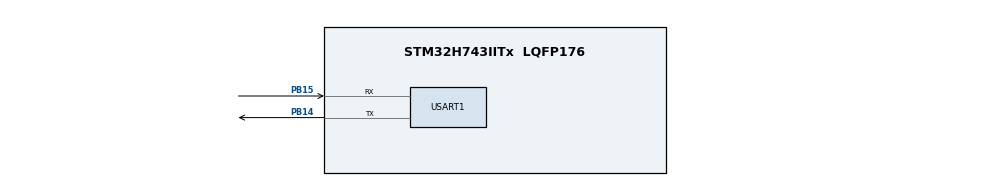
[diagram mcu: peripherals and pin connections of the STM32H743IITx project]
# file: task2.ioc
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CORTEX_M7.CPU_DCache=Enabled
CORTEX_M7.CPU_ICache=Enabled
FREERTOS.Tasks01=defaultTask,24,128,StartDefaultTask,Default,NULL,Dynamic,NULL,NULL
Mcu.Family=STM32H7
Mcu.Name=STM32H743IITx
Mcu.Package=LQFP176
NVIC.PriorityGroup=NVIC_PRIORITYGROUP_4
NVIC.USART1_IRQn=true\:5\:0\:false\:false\:true\:true\:true\:true
PB14.Mode=Asynchronous
PB14.Signal=USART1_TX
PB15.Mode=Asynchronous
PB15.Signal=USART1_RX
PH0-OSC_IN\ (PH0).Mode=HSE-External-Oscillator
PH0-OSC_IN\ (PH0).Signal=RCC_OSC_IN
PH1-OSC_OUT\ (PH1).Mode=HSE-External-Oscillator
PH1-OSC_OUT\ (PH1).Signal=RCC_OSC_OUT
ProjectManager.HeapSize=0x200
ProjectManager.StackSize=0x400
ProjectManager.TargetToolchain=EWARM V8.32
RCC.ADCFreq_Value=50390625
RCC.APB1Freq_Value=100000000
RCC.APB2Freq_Value=100000000
RCC.APB3Freq_Value=100000000
RCC.APB4Freq_Value=100000000
RCC.CortexFreq_Value=400000000
RCC.D1PPRE=RCC_APB3_DIV2
RCC.D2PPRE1=RCC_APB1_DIV2
RCC.D2PPRE2=RCC_APB2_DIV2
RCC.D3PPRE=RCC_APB4_DIV2
RCC.DIVM1=2
RCC.DIVN1=64
RCC.HCLKFreq_Value=200000000
RCC.HPRE=RCC_HCLK_DIV2
RCC.PLLFRACN=0
RCC.PLLSourceVirtual=RCC_PLLSOURCE_HSE
RCC.SYSCLKFreq_VALUE=400000000
RCC.SYSCLKSource=RCC_SYSCLKSOURCE_PLLCLK
RCC.USBFreq_Value=400000000
USART1.VirtualMode-Asynchronous=VM_ASYNC
VP_FREERTOS_VS_CMSIS_V2.Mode=CMSIS_V2
board=custom

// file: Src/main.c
/* USER CODE BEGIN Header */
/**
  ******************************************************************************
  * @file           : main.c
  * @brief          : Main program body
  ******************************************************************************
  * @attention
  *
  * <h2><center>&copy; Copyright (c) 2019 STMicroelectronics.
  * All rights reserved.</center></h2>
  *
  * This software component is licensed by ST under Ultimate Liberty license
  * SLA0044, the "License"; You may not use this file except in compliance with
  * the License. You may obtain a copy of the License at:
  *                             www.st.com/SLA0044
  *
  ******************************************************************************
  */
/* USER CODE END Header */

#include "main.h"
#include "cmsis_os.h"
#include "usart.h"

void SystemClock_Config(void);
void MX_FREERTOS_Init(void);

int main(void)
{

  /* Enable I-Cache---------------------------------------------------------*/
  SCB_EnableICache();

  /* Enable D-Cache---------------------------------------------------------*/
  SCB_EnableDCache();

  /* MCU Configuration--------------------------------------------------------*/

  /* Reset of all peripherals, Initializes the Flash interface and the Systick. */
  HAL_Init();

  /* Configure the system clock */
  SystemClock_Config();

  /* Initialize all configured peripherals */
  MX_USART1_UART_Init();
  /* USER CODE BEGIN 2 */
  BSP_LED_Init();

 // SEGGER_SYSVIEW_Conf();
  SEGGER_RTT_Init();
  /* USER CODE END 2 */

  /* Call init function for freertos objects (in freertos.c) */
  MX_FREERTOS_Init();

  /* Start scheduler */
  osKernelStart();

  /* We should never get here as control is now taken by the scheduler */

  /* Infinite loop */
  while (1)
  {

  }
}

void SystemClock_Config(void)
{
  RCC_OscInitTypeDef RCC_OscInitStruct = {0};
  RCC_ClkInitTypeDef RCC_ClkInitStruct = {0};
  RCC_PeriphCLKInitTypeDef PeriphClkInitStruct = {0};

  /** Supply configuration update enable
  */
  HAL_PWREx_ConfigSupply(PWR_LDO_SUPPLY);
  /** Configure the main internal regulator output voltage
  */
  __HAL_PWR_VOLTAGESCALING_CONFIG(PWR_REGULATOR_VOLTAGE_SCALE1);

  while(!__HAL_PWR_GET_FLAG(PWR_FLAG_VOSRDY)) {}
  /** Initializes the CPU, AHB and APB busses clocks
  */
  RCC_OscInitStruct.OscillatorType = RCC_OSCILLATORTYPE_HSE;
  RCC_OscInitStruct.HSEState = RCC_HSE_ON;
  RCC_OscInitStruct.PLL.PLLState = RCC_PLL_ON;
  RCC_OscInitStruct.PLL.PLLSource = RCC_PLLSOURCE_HSE;
  RCC_OscInitStruct.PLL.PLLM = 2;
  RCC_OscInitStruct.PLL.PLLN = 64;
  RCC_OscInitStruct.PLL.PLLP = 2;
  RCC_OscInitStruct.PLL.PLLQ = 2;
  RCC_OscInitStruct.PLL.PLLR = 2;
  RCC_OscInitStruct.PLL.PLLRGE = RCC_PLL1VCIRANGE_3;
  RCC_OscInitStruct.PLL.PLLVCOSEL = RCC_PLL1VCOWIDE;
  RCC_OscInitStruct.PLL.PLLFRACN = 0;
  if (HAL_RCC_OscConfig(&RCC_OscInitStruct) != HAL_OK)
  {
    Error_Handler();
  }
  /** Initializes the CPU, AHB and APB busses clocks
  */
  RCC_ClkInitStruct.ClockType = RCC_CLOCKTYPE_HCLK|RCC_CLOCKTYPE_SYSCLK
                              |RCC_CLOCKTYPE_PCLK1|RCC_CLOCKTYPE_PCLK2
                              |RCC_CLOCKTYPE_D3PCLK1|RCC_CLOCKTYPE_D1PCLK1;
  RCC_ClkInitStruct.SYSCLKSource = RCC_SYSCLKSOURCE_PLLCLK;
  RCC_ClkInitStruct.SYSCLKDivider = RCC_SYSCLK_DIV1;
  RCC_ClkInitStruct.AHBCLKDivider = RCC_HCLK_DIV2;
  RCC_ClkInitStruct.APB3CLKDivider = RCC_APB3_DIV2;
  RCC_ClkInitStruct.APB1CLKDivider = RCC_APB1_DIV2;
  RCC_ClkInitStruct.APB2CLKDivider = RCC_APB2_DIV2;
  RCC_ClkInitStruct.APB4CLKDivider = RCC_APB4_DIV2;

  if (HAL_RCC_ClockConfig(&RCC_ClkInitStruct, FLASH_LATENCY_2) != HAL_OK)
  {
    Error_Handler();
  }
  PeriphClkInitStruct.PeriphClockSelection = RCC_PERIPHCLK_USART1;
  PeriphClkInitStruct.Usart16ClockSelection = RCC_USART16CLKSOURCE_D2PCLK2;
  if (HAL_RCCEx_PeriphCLKConfig(&PeriphClkInitStruct) != HAL_OK)
  {
    Error_Handler();
  }
}

void Error_Handler(void)
{
}

/************************ (C) COPYRIGHT STMicroelectronics *****END OF FILE****/

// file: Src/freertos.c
/* USER CODE BEGIN Header */
/**
  ******************************************************************************
  * File Name          : freertos.c
  * Description        : Code for freertos applications
  ******************************************************************************
  * @attention
  *
  * <h2><center>&copy; Copyright (c) 2019 STMicroelectronics.
  * All rights reserved.</center></h2>
  *
  * This software component is licensed by ST under Ultimate Liberty license
  * SLA0044, the "License"; You may not use this file except in compliance with
  * the License. You may obtain a copy of the License at:
  *                             www.st.com/SLA0044
  *
  ******************************************************************************
  */
/* USER CODE END Header */

#include "FreeRTOS.h"
#include "task.h"
#include "main.h"
#include "cmsis_os.h"

/* USER CODE BEGIN PTD */
#define LED_TASK
/* USER CODE END PTD */

/* USER CODE BEGIN PM */
#ifdef LED_TASK
osThreadId_t ledTaskHandle;
void LedTask(void *argument);
#endif
/* USER CODE END PM */

osThreadId_t defaultTaskHandle;

void StartDefaultTask(void *argument);

void MX_FREERTOS_Init(void); /* (MISRA C 2004 rule 8.1) */

void MX_FREERTOS_Init(void) {
osKernelInitialize();

  /* Create the thread(s) */
  /* definition and creation of defaultTask */
  const osThreadAttr_t defaultTask_attributes = {
    .name = "defaultTask",
    .priority = (osPriority_t) osPriorityNormal,
    .stack_size = 1024
  };
  defaultTaskHandle = osThreadNew(StartDefaultTask, NULL, &defaultTask_attributes);

  /* USER CODE BEGIN RTOS_THREADS */
  #ifdef LED_TASK
    const osThreadAttr_t ledTask_attributes = {
        .name = "LedTask",
        .priority = (osPriority_t)osPriorityNormal1,
        .stack_size = 128};
    ledTaskHandle = osThreadNew(LedTask, NULL, &ledTask_attributes);
#endif
  /* add threads, ... */
  /* USER CODE END RTOS_THREADS */

}

void StartDefaultTask(void *argument)
{
  /* USER CODE BEGIN StartDefaultTask */
  /* Infinite loop */
  for(;;)
  {
      BSP_LED_Toggle(USER_LD1);
      SEGGER_RTT_printf(0,"\r\nhello,rtt\r\n");
      osDelay(500);
  }
  /* USER CODE END StartDefaultTask */
}

/* USER CODE BEGIN Application */
void LedTask(void *argument)
{
     SEGGER_RTT_ConfigUpBuffer(0, NULL, NULL, 0, SEGGER_RTT_MODE_BLOCK_IF_FIFO_FULL);

    for(;;)
    {
      BSP_LED_Toggle(USER_LD2);
      osDelay(500);
    }
}
/* USER CODE END Application */

/************************ (C) COPYRIGHT STMicroelectronics *****END OF FILE****/
